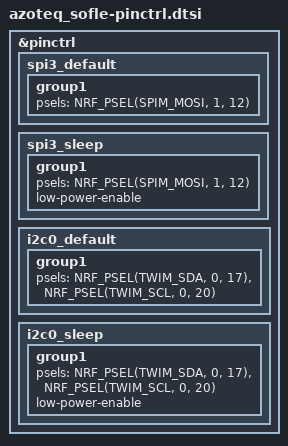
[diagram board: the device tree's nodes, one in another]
&pinctrl {

    spi3_default: spi3_default {
        group1 {
            psels = <NRF_PSEL(SPIM_MOSI, 1, 12)>; // WS2812_VEXT_DATA - old (SPIM_MOSI, 0, 6)
        };
    };

    spi3_sleep: spi3_sleep {
        group1 {
            psels = <NRF_PSEL(SPIM_MOSI, 1, 12)>;
            low-power-enable;
        };
    };

    i2c0_default: i2c0_default {
        group1 {
            psels = <NRF_PSEL(TWIM_SDA, 0, 17)>,
                <NRF_PSEL(TWIM_SCL, 0, 20)>; // OLD: (TWIM_SDA, 0, 22) | (TWIM_SCL, 0, 24)
        };
    };

    i2c0_sleep: i2c0_sleep {
        group1 {
            psels = <NRF_PSEL(TWIM_SDA, 0, 17)>,
                <NRF_PSEL(TWIM_SCL, 0, 20)>;
            low-power-enable;
        };
    };

};
